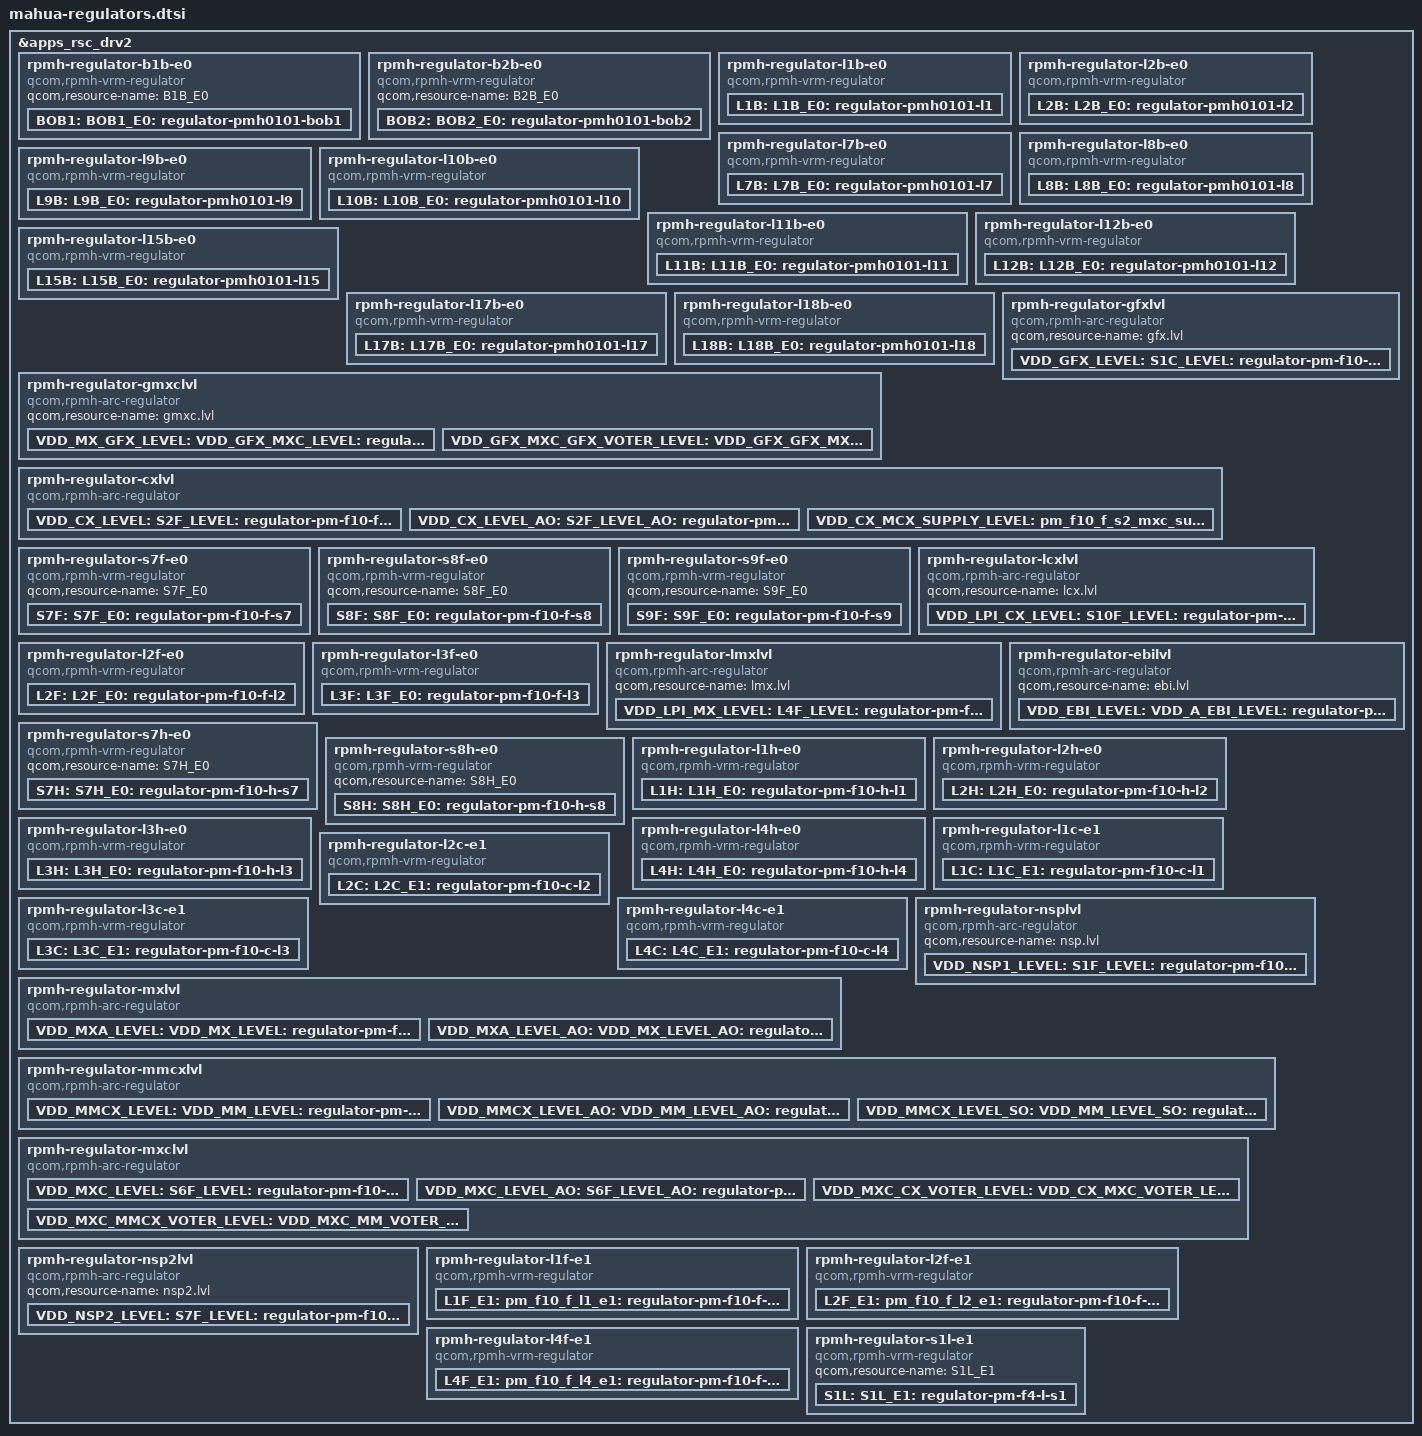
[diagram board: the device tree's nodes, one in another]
// SPDX-License-Identifier: BSD-3-Clause
/*
 * Copyright (c) Qualcomm Technologies, Inc. and/or its subsidiaries.
 */

#include <dt-bindings/regulator/qcom,rpmh-regulator-levels.h>

&apps_rsc_drv2 {
	rpmh-regulator-b1b-e0 {
		compatible = "qcom,rpmh-vrm-regulator";
		qcom,resource-name = "B1B_E0";

		BOB1: BOB1_E0: pmh0101_bob1: regulator-pmh0101-bob1 {
			regulator-name = "pmh0101_bob1";
			qcom,set = <RPMH_REGULATOR_SET_ALL>;
			regulator-min-microvolt = <3300000>;
			regulator-max-microvolt = <4224000>;
			qcom,init-voltage = <3424000>;
		};
	};

	rpmh-regulator-b2b-e0 {
		compatible = "qcom,rpmh-vrm-regulator";
		qcom,resource-name = "B2B_E0";

		BOB2: BOB2_E0: pmh0101_bob2: regulator-pmh0101-bob2 {
			regulator-name = "pmh0101_bob2";
			qcom,set = <RPMH_REGULATOR_SET_ALL>;
			regulator-min-microvolt = <2720000>;
			regulator-max-microvolt = <3008000>;
			qcom,init-voltage = <2720000>;
		};
	};

	rpmh-regulator-l1b-e0 {
		compatible = "qcom,rpmh-vrm-regulator";
		qcom,resource-name = "L1B_E0";
		qcom,regulator-type = "pmic7-ldo";
		qcom,supported-modes = <RPMH_REGULATOR_MODE_LPM
					RPMH_REGULATOR_MODE_HPM>;
		qcom,mode-threshold-currents = <0 30000>;

		L1B: L1B_E0: pmh0101_l1: regulator-pmh0101-l1 {
			regulator-name = "pmh0101_l1";
			qcom,set = <RPMH_REGULATOR_SET_ALL>;
			regulator-min-microvolt = <1800000>;
			regulator-max-microvolt = <1800000>;
			qcom,init-voltage = <1800000>;
			qcom,init-mode = <RPMH_REGULATOR_MODE_HPM>;
		};
	};

	rpmh-regulator-l2b-e0 {
		compatible = "qcom,rpmh-vrm-regulator";
		qcom,resource-name = "L2B_E0";
		qcom,regulator-type = "pmic7-ldo";
		qcom,supported-modes = <RPMH_REGULATOR_MODE_LPM
					RPMH_REGULATOR_MODE_HPM>;
		qcom,mode-threshold-currents = <0 20000>;

		L2B: L2B_E0: pmh0101_l2: regulator-pmh0101-l2 {
			regulator-name = "pmh0101_l2";
			qcom,set = <RPMH_REGULATOR_SET_ALL>;
			regulator-min-microvolt = <1800000>;
			regulator-max-microvolt = <3300000>;
			qcom,init-voltage = <3300000>;
			qcom,init-mode = <RPMH_REGULATOR_MODE_HPM>;
		};
	};

	rpmh-regulator-l7b-e0 {
		compatible = "qcom,rpmh-vrm-regulator";
		qcom,resource-name = "L7B_E0";
		qcom,regulator-type = "pmic7-ldo";
		qcom,supported-modes = <RPMH_REGULATOR_MODE_LPM
					RPMH_REGULATOR_MODE_HPM>;
		qcom,mode-threshold-currents = <0 20000>;

		L7B: L7B_E0: pmh0101_l7: regulator-pmh0101-l7 {
			regulator-name = "pmh0101_l7";
			qcom,set = <RPMH_REGULATOR_SET_ALL>;
			regulator-min-microvolt = <3000000>;
			regulator-max-microvolt = <3300000>;
			qcom,init-voltage = <3000000>;
			qcom,init-mode = <RPMH_REGULATOR_MODE_HPM>;
		};
	};

	rpmh-regulator-l8b-e0 {
		compatible = "qcom,rpmh-vrm-regulator";
		qcom,resource-name = "L8B_E0";
		qcom,regulator-type = "pmic7-ldo";
		qcom,supported-modes = <RPMH_REGULATOR_MODE_LPM
					RPMH_REGULATOR_MODE_HPM>;
		qcom,mode-threshold-currents = <0 10000>;

		L8B: L8B_E0: pmh0101_l8: regulator-pmh0101-l8 {
			regulator-name = "pmh0101_l8";
			qcom,set = <RPMH_REGULATOR_SET_ALL>;
			regulator-min-microvolt = <3304000>;
			regulator-max-microvolt = <3400000>;
			qcom,init-voltage = <3304000>;
			qcom,init-mode = <RPMH_REGULATOR_MODE_HPM>;
		};
	};

	rpmh-regulator-l9b-e0 {
		compatible = "qcom,rpmh-vrm-regulator";
		qcom,resource-name = "L9B_E0";
		qcom,regulator-type = "pmic7-ldo";
		qcom,supported-modes = <RPMH_REGULATOR_MODE_LPM
					RPMH_REGULATOR_MODE_HPM>;
		qcom,mode-threshold-currents = <0 80000>;

		L9B: L9B_E0: pmh0101_l9: regulator-pmh0101-l9 {
			regulator-name = "pmh0101_l9";
			qcom,set = <RPMH_REGULATOR_SET_ALL>;
			regulator-min-microvolt = <2960000>;
			regulator-max-microvolt = <2960000>;
			qcom,init-voltage = <2960000>;
			qcom,init-mode = <RPMH_REGULATOR_MODE_HPM>;
		};
	};

	rpmh-regulator-l10b-e0 {
		compatible = "qcom,rpmh-vrm-regulator";
		qcom,resource-name = "L10B_E0";
		qcom,regulator-type = "pmic7-ldo";
		qcom,supported-modes = <RPMH_REGULATOR_MODE_LPM
					RPMH_REGULATOR_MODE_HPM>;
		qcom,mode-threshold-currents = <0 30000>;

		L10B: L10B_E0: pmh0101_l10: regulator-pmh0101-l10 {
			regulator-name = "pmh0101_l10";
			qcom,set = <RPMH_REGULATOR_SET_ALL>;
			regulator-min-microvolt = <1800000>;
			regulator-max-microvolt = <1800000>;
			qcom,init-voltage = <1800000>;
			qcom,init-mode = <RPMH_REGULATOR_MODE_HPM>;
		};
	};

	rpmh-regulator-l11b-e0 {
		compatible = "qcom,rpmh-vrm-regulator";
		qcom,resource-name = "L11B_E0";
		qcom,regulator-type = "pmic7-ldo";
		qcom,supported-modes = <RPMH_REGULATOR_MODE_LPM
					RPMH_REGULATOR_MODE_HPM>;
		qcom,mode-threshold-currents = <0 30000>;

		L11B: L11B_E0: pmh0101_l11: regulator-pmh0101-l11 {
			regulator-name = "pmh0101_l11";
			qcom,set = <RPMH_REGULATOR_SET_ALL>;
			regulator-min-microvolt = <1200000>;
			regulator-max-microvolt = <1200000>;
			qcom,init-voltage = <1200000>;
			qcom,init-mode = <RPMH_REGULATOR_MODE_HPM>;
		};
	};

	rpmh-regulator-l12b-e0 {
		compatible = "qcom,rpmh-vrm-regulator";
		qcom,resource-name = "L12B_E0";
		qcom,regulator-type = "pmic7-ldo";
		qcom,supported-modes = <RPMH_REGULATOR_MODE_LPM
					RPMH_REGULATOR_MODE_HPM>;
		qcom,mode-threshold-currents = <0 30000>;

		L12B: L12B_E0: pmh0101_l12: regulator-pmh0101-l12 {
			regulator-name = "pmh0101_l12";
			qcom,set = <RPMH_REGULATOR_SET_ALL>;
			regulator-min-microvolt = <1200000>;
			regulator-max-microvolt = <1260000>;
			qcom,init-voltage = <1200000>;
			qcom,init-mode = <RPMH_REGULATOR_MODE_HPM>;
		};
	};

	rpmh-regulator-l15b-e0 {
		compatible = "qcom,rpmh-vrm-regulator";
		qcom,resource-name = "L15B_E0";
		qcom,regulator-type = "pmic7-ldo";
		qcom,supported-modes = <RPMH_REGULATOR_MODE_LPM
					RPMH_REGULATOR_MODE_HPM>;
		qcom,mode-threshold-currents = <0 30000>;

		L15B: L15B_E0: pmh0101_l15: regulator-pmh0101-l15 {
			regulator-name = "pmh0101_l15";
			qcom,set = <RPMH_REGULATOR_SET_ALL>;
			regulator-min-microvolt = <1800000>;
			regulator-max-microvolt = <1800000>;
			qcom,init-voltage = <1800000>;
			qcom,init-mode = <RPMH_REGULATOR_MODE_HPM>;
		};
	};

	rpmh-regulator-l17b-e0 {
		compatible = "qcom,rpmh-vrm-regulator";
		qcom,resource-name = "L17B_E0";
		qcom,regulator-type = "pmic7-ldo";
		qcom,supported-modes = <RPMH_REGULATOR_MODE_LPM
					RPMH_REGULATOR_MODE_HPM>;
		qcom,mode-threshold-currents = <0 80000>;

		L17B: L17B_E0: pmh0101_l17: regulator-pmh0101-l17 {
			regulator-name = "pmh0101_l17";
			qcom,set = <RPMH_REGULATOR_SET_ALL>;
			regulator-min-microvolt = <2500000>;
			regulator-max-microvolt = <2600000>;
			qcom,init-voltage = <2504000>;
			qcom,init-mode = <RPMH_REGULATOR_MODE_HPM>;
		};
	};

	rpmh-regulator-l18b-e0 {
		compatible = "qcom,rpmh-vrm-regulator";
		qcom,resource-name = "L18B_E0";
		qcom,regulator-type = "pmic7-ldo";
		qcom,supported-modes = <RPMH_REGULATOR_MODE_LPM
					RPMH_REGULATOR_MODE_HPM>;
		qcom,mode-threshold-currents = <0 30000>;

		L18B: L18B_E0: pmh0101_l18: regulator-pmh0101-l18 {
			regulator-name = "pmh0101_l18";
			qcom,set = <RPMH_REGULATOR_SET_ALL>;
			regulator-min-microvolt = <1200000>;
			regulator-max-microvolt = <1200000>;
			qcom,init-voltage = <1200000>;
			qcom,init-mode = <RPMH_REGULATOR_MODE_HPM>;
		};
	};

	rpmh-regulator-gfxlvl {
		compatible = "qcom,rpmh-arc-regulator";
		qcom,resource-name = "gfx.lvl";

		VDD_GFX_LEVEL: S1C_LEVEL: S1C_E0_LEVEL:
		pm_f10_c_s1_level: regulator-pm-f10-c-s1-level {
			regulator-name = "pm_f10_c_s1_level";
			qcom,set = <RPMH_REGULATOR_SET_ALL>;
			regulator-min-microvolt =
				<RPMH_REGULATOR_LEVEL_RETENTION>;
			regulator-max-microvolt =
				<RPMH_REGULATOR_LEVEL_MAX>;
			qcom,init-voltage-level =
				<RPMH_REGULATOR_LEVEL_RETENTION>;
		};
	};

	rpmh-regulator-gmxclvl {
		compatible = "qcom,rpmh-arc-regulator";
		qcom,resource-name = "gmxc.lvl";

		VDD_MX_GFX_LEVEL: VDD_GFX_MXC_LEVEL: S8C_LEVEL: S8C_E0_LEVEL:
		pm_f10_c_s8_level: regulator-pm-f10-c-s8-level {
			regulator-name = "pm_f10_c_s8_level";
			qcom,set = <RPMH_REGULATOR_SET_ALL>;
			regulator-min-microvolt =
				<RPMH_REGULATOR_LEVEL_RETENTION>;
			regulator-max-microvolt =
				<RPMH_REGULATOR_LEVEL_MAX>;
			qcom,init-voltage-level =
				<RPMH_REGULATOR_LEVEL_RETENTION>;
		};

		VDD_GFX_MXC_GFX_VOTER_LEVEL: VDD_GFX_GFX_MXC_VOTER_LEVEL:
		regulator-pm-f10-c-s8-gfx-voter-level {
			regulator-name = "pm_f10_c_s8_gfx_voter_level";
			qcom,set = <RPMH_REGULATOR_SET_ALL>;
			pm_f10_c_s8_gfx_voter_level-parent-supply =
				<&VDD_GFX_LEVEL>;
			regulator-min-microvolt =
				<RPMH_REGULATOR_LEVEL_MIN_SVS>;
			regulator-max-microvolt =
				<RPMH_REGULATOR_LEVEL_MAX>;
			qcom,init-voltage-level =
				<RPMH_REGULATOR_LEVEL_MIN_SVS>;
		};
	};

	rpmh-regulator-cxlvl {
		compatible = "qcom,rpmh-arc-regulator";
		qcom,resource-name = "cx.lvl";
		proxy-supply = <&VDD_CX_LEVEL>;

		VDD_CX_LEVEL: S2F_LEVEL: S2F_E0_LEVEL:
			pm_f10_f_s2_level: regulator-pm-f10-f-s2-level {
			regulator-name = "pm_f10_f_s2_level";
			qcom,set = <RPMH_REGULATOR_SET_ALL>;
			regulator-min-microvolt =
				<RPMH_REGULATOR_LEVEL_RETENTION>;
			regulator-max-microvolt =
				<RPMH_REGULATOR_LEVEL_MAX>;
			qcom,init-voltage-level =
				<RPMH_REGULATOR_LEVEL_TURBO>;
			qcom,proxy-consumer-enable;
			qcom,proxy-consumer-voltage =
				<RPMH_REGULATOR_LEVEL_TURBO
				RPMH_REGULATOR_LEVEL_MAX>;
		};

		VDD_CX_LEVEL_AO: S2F_LEVEL_AO: S2F_E0_LEVEL_AO:
			pm_f10_f_s2_level_ao: regulator-pm-f10-f-s2-level-ao {
			regulator-name = "pm_f10_f_s2_level_ao";
			qcom,set = <RPMH_REGULATOR_SET_ACTIVE>;
			regulator-min-microvolt =
				<RPMH_REGULATOR_LEVEL_RETENTION>;
			regulator-max-microvolt =
				<RPMH_REGULATOR_LEVEL_MAX>;
			qcom,init-voltage-level =
				<RPMH_REGULATOR_LEVEL_RETENTION>;
		};

		VDD_CX_MCX_SUPPLY_LEVEL:
		pm_f10_f_s2_mxc_sup_level: regulator-pm-f10-s2-mxc-sup-level {
			regulator-name = "pm_f10_f_s2_mxc_sup_level";
			qcom,set = <RPMH_REGULATOR_SET_ALL>;
			regulator-min-microvolt =
				<RPMH_REGULATOR_LEVEL_MIN_SVS>;
			regulator-max-microvolt =
				<RPMH_REGULATOR_LEVEL_MAX>;
			qcom,init-voltage-level =
				<RPMH_REGULATOR_LEVEL_MIN_SVS>;
		};
	};

	rpmh-regulator-s7f-e0 {
		compatible = "qcom,rpmh-vrm-regulator";
		qcom,resource-name = "S7F_E0";

		S7F: S7F_E0: pm_f10_f_s7: regulator-pm-f10-f-s7 {
			regulator-name = "pm_f10_f_s7";
			qcom,set = <RPMH_REGULATOR_SET_ALL>;
			regulator-min-microvolt = <1320000>;
			regulator-max-microvolt = <1352000>;
			qcom,init-voltage = <1320000>;
		};
	};

	rpmh-regulator-s8f-e0 {
		compatible = "qcom,rpmh-vrm-regulator";
		qcom,resource-name = "S8F_E0";

		S8F: S8F_E0: pm_f10_f_s8: regulator-pm-f10-f-s8 {
			regulator-name = "pm_f10_f_s8";
			qcom,set = <RPMH_REGULATOR_SET_ALL>;
			regulator-min-microvolt = <952000>;
			regulator-max-microvolt = <1100000>;
			qcom,init-voltage = <952000>;
		};
	};

	rpmh-regulator-s9f-e0 {
		compatible = "qcom,rpmh-vrm-regulator";
		qcom,resource-name = "S9F_E0";

		S9F: S9F_E0: pm_f10_f_s9: regulator-pm-f10-f-s9 {
			regulator-name = "pm_f10_f_s9";
			qcom,set = <RPMH_REGULATOR_SET_ALL>;
			regulator-min-microvolt = <1900000>;
			regulator-max-microvolt = <2000000>;
			qcom,init-voltage = <1900000>;
		};
	};

	rpmh-regulator-lcxlvl {
		compatible = "qcom,rpmh-arc-regulator";
		qcom,resource-name = "lcx.lvl";

		VDD_LPI_CX_LEVEL: S10F_LEVEL: S10F_E0_LEVEL:
		pm_f10_f_s10_level: regulator-pm-f10-f-s10-level {
			regulator-name = "pm_f10_f_s10_level";
			qcom,set = <RPMH_REGULATOR_SET_ALL>;
			regulator-min-microvolt =
				<RPMH_REGULATOR_LEVEL_RETENTION>;
			regulator-max-microvolt =
				<RPMH_REGULATOR_LEVEL_MAX>;
			qcom,init-voltage-level =
				<RPMH_REGULATOR_LEVEL_RETENTION>;
		};
	};

	rpmh-regulator-l2f-e0 {
		compatible = "qcom,rpmh-vrm-regulator";
		qcom,resource-name = "L2F_E0";
		qcom,regulator-type = "pmic7-ldo";
		qcom,supported-modes = <RPMH_REGULATOR_MODE_LPM
					RPMH_REGULATOR_MODE_HPM>;
		qcom,mode-threshold-currents = <0 30000>;

		L2F: L2F_E0: pm_f10_f_l2: regulator-pm-f10-f-l2 {
			regulator-name = "pm_f10_f_l2";
			qcom,set = <RPMH_REGULATOR_SET_ALL>;
			regulator-min-microvolt = <936000>;
			regulator-max-microvolt = <952000>;
			qcom,init-voltage = <944000>;
			qcom,init-mode = <RPMH_REGULATOR_MODE_HPM>;
		};
	};

	rpmh-regulator-l3f-e0 {
		compatible = "qcom,rpmh-vrm-regulator";
		qcom,resource-name = "L3F_E0";
		qcom,regulator-type = "pmic7-ldo";
		qcom,supported-modes = <RPMH_REGULATOR_MODE_LPM
					RPMH_REGULATOR_MODE_HPM>;
		qcom,mode-threshold-currents = <0 30000>;

		L3F: L3F_E0: pm_f10_f_l3: regulator-pm-f10-f-l3 {
			regulator-name = "pm_f10_f_l3";
			qcom,set = <RPMH_REGULATOR_SET_ALL>;
			regulator-min-microvolt = <912000>;
			regulator-max-microvolt = <952000>;
			qcom,init-voltage = <912000>;
			qcom,init-mode = <RPMH_REGULATOR_MODE_HPM>;
		};
	};

	rpmh-regulator-lmxlvl {
		compatible = "qcom,rpmh-arc-regulator";
		qcom,resource-name = "lmx.lvl";

		VDD_LPI_MX_LEVEL:
		L4F_LEVEL: L4F_E0_LEVEL:
		pm_f10_f_l4_level: regulator-pm-f10-f-l4-level {
			regulator-name = "pm_f10_f_l4_level";
			qcom,set = <RPMH_REGULATOR_SET_ALL>;
			regulator-min-microvolt =
				<RPMH_REGULATOR_LEVEL_RETENTION>;
			regulator-max-microvolt =
				<RPMH_REGULATOR_LEVEL_MAX>;
			qcom,init-voltage-level =
				<RPMH_REGULATOR_LEVEL_RETENTION>;
		};
	};

	rpmh-regulator-ebilvl {
		compatible = "qcom,rpmh-arc-regulator";
		qcom,resource-name = "ebi.lvl";

		VDD_EBI_LEVEL: VDD_A_EBI_LEVEL: S6H_LEVEL: S6H_E0_LEVEL:
		pm_f10_h_s6_level: regulator-pm-f10-h-s6-level {
			regulator-name = "pm_f10_h_s6_level";
			qcom,set = <RPMH_REGULATOR_SET_ALL>;
			regulator-min-microvolt =
				<RPMH_REGULATOR_LEVEL_RETENTION>;
			regulator-max-microvolt =
				<RPMH_REGULATOR_LEVEL_MAX>;
			qcom,init-voltage-level =
				<RPMH_REGULATOR_LEVEL_RETENTION>;
		};
	};

	rpmh-regulator-s7h-e0 {
		compatible = "qcom,rpmh-vrm-regulator";
		qcom,resource-name = "S7H_E0";

		S7H: S7H_E0: pm_f10_h_s7: regulator-pm-f10-h-s7 {
			regulator-name = "pm_f10_h_s7";
			qcom,set = <RPMH_REGULATOR_SET_ALL>;
			regulator-min-microvolt = <870000>;
			regulator-max-microvolt = <1100000>;
			qcom,init-voltage = <904000>;
		};
	};

	rpmh-regulator-s8h-e0 {
		compatible = "qcom,rpmh-vrm-regulator";
		qcom,resource-name = "S8H_E0";

		S8H: S8H_E0: pm_f10_h_s8: regulator-pm-f10-h-s8 {
			regulator-name = "pm_f10_h_s8";
			qcom,set = <RPMH_REGULATOR_SET_ALL>;
			regulator-min-microvolt = <300000>;
			regulator-max-microvolt = <570000>;
			qcom,init-voltage = <500000>;
		};
	};

	rpmh-regulator-l1h-e0 {
		compatible = "qcom,rpmh-vrm-regulator";
		qcom,resource-name = "L1H_E0";
		qcom,regulator-type = "pmic7-ldo";
		qcom,supported-modes = <RPMH_REGULATOR_MODE_LPM
					RPMH_REGULATOR_MODE_HPM>;
		qcom,mode-threshold-currents = <0 30000>;

		L1H: L1H_E0: pm_f10_h_l1: regulator-pm-f10-h-l1 {
			regulator-name = "pm_f10_h_l1";
			qcom,set = <RPMH_REGULATOR_SET_ALL>;
			regulator-min-microvolt = <912000>;
			regulator-max-microvolt = <952000>;
			qcom,init-voltage = <936000>;
			qcom,init-mode = <RPMH_REGULATOR_MODE_HPM>;
		};
	};

	rpmh-regulator-l2h-e0 {
		compatible = "qcom,rpmh-vrm-regulator";
		qcom,resource-name = "L2H_E0";
		qcom,regulator-type = "pmic7-ldo";
		qcom,supported-modes = <RPMH_REGULATOR_MODE_LPM
					RPMH_REGULATOR_MODE_HPM>;
		qcom,mode-threshold-currents = <0 30000>;

		L2H: L2H_E0: pm_f10_h_l2: regulator-pm-f10-h-l2 {
			regulator-name = "pm_f10_h_l2";
			qcom,set = <RPMH_REGULATOR_SET_ALL>;
			regulator-min-microvolt = <880000>;
			regulator-max-microvolt = <952000>;
			qcom,init-voltage = <880000>;
			qcom,init-mode = <RPMH_REGULATOR_MODE_HPM>;
		};
	};

	rpmh-regulator-l3h-e0 {
		compatible = "qcom,rpmh-vrm-regulator";
		qcom,resource-name = "L3H_E0";
		qcom,regulator-type = "pmic7-ldo";
		qcom,supported-modes = <RPMH_REGULATOR_MODE_LPM
					RPMH_REGULATOR_MODE_HPM>;
		qcom,mode-threshold-currents = <0 30000>;

		L3H: L3H_E0: pm_f10_h_l3: regulator-pm-f10-h-l3 {
			regulator-name = "pm_f10_h_l3";
			qcom,set = <RPMH_REGULATOR_SET_ALL>;
			regulator-min-microvolt = <1800000>;
			regulator-max-microvolt = <1800000>;
			qcom,init-voltage = <1800000>;
			qcom,init-mode = <RPMH_REGULATOR_MODE_HPM>;
		};
	};

	rpmh-regulator-l4h-e0 {
		compatible = "qcom,rpmh-vrm-regulator";
		qcom,resource-name = "L4H_E0";
		qcom,regulator-type = "pmic7-ldo";
		qcom,supported-modes = <RPMH_REGULATOR_MODE_LPM
					RPMH_REGULATOR_MODE_HPM>;
		qcom,mode-threshold-currents = <0 30000>;

		L4H: L4H_E0: pm_f10_h_l4: regulator-pm-f10-h-l4 {
			regulator-name = "pm_f10_h_l4";
			qcom,set = <RPMH_REGULATOR_SET_ALL>;
			regulator-min-microvolt = <1200000>;
			regulator-max-microvolt = <1200000>;
			qcom,init-voltage = <1200000>;
			qcom,init-mode = <RPMH_REGULATOR_MODE_HPM>;
		};
	};

	rpmh-regulator-l1c-e1 {
		compatible = "qcom,rpmh-vrm-regulator";
		qcom,resource-name = "L1C_E1";
		qcom,regulator-type = "pmic7-ldo";
		qcom,supported-modes = <RPMH_REGULATOR_MODE_LPM
					RPMH_REGULATOR_MODE_HPM>;
		qcom,mode-threshold-currents = <0 30000>;

		L1C: L1C_E1: pm_f10_c_l1: regulator-pm-f10-c-l1 {
			regulator-name = "pm_f10_c_l1";
			qcom,set = <RPMH_REGULATOR_SET_ALL>;
			regulator-min-microvolt = <912000>;
			regulator-max-microvolt = <952000>;
			qcom,init-voltage = <912000>;
			qcom,init-mode = <RPMH_REGULATOR_MODE_HPM>;
		};
	};

	rpmh-regulator-l2c-e1 {
		compatible = "qcom,rpmh-vrm-regulator";
		qcom,resource-name = "L2C_E1";
		qcom,regulator-type = "pmic7-ldo";
		qcom,supported-modes = <RPMH_REGULATOR_MODE_LPM
					RPMH_REGULATOR_MODE_HPM>;
		qcom,mode-threshold-currents = <0 30000>;

		L2C: L2C_E1: pm_f10_c_l2: regulator-pm-f10-c-l2 {
			regulator-name = "pm_f10_c_l2";
			qcom,set = <RPMH_REGULATOR_SET_ALL>;
			regulator-min-microvolt = <1200000>;
			regulator-max-microvolt = <1252000>;
			qcom,init-voltage = <1216000>;
			qcom,init-mode = <RPMH_REGULATOR_MODE_HPM>;
		};
	};

	rpmh-regulator-l3c-e1 {
		compatible = "qcom,rpmh-vrm-regulator";
		qcom,resource-name = "L3C_E1";
		qcom,regulator-type = "pmic7-ldo";
		qcom,supported-modes = <RPMH_REGULATOR_MODE_LPM
					RPMH_REGULATOR_MODE_HPM>;
		qcom,mode-threshold-currents = <0 30000>;

		L3C: L3C_E1: pm_f10_c_l3: regulator-pm-f10-c-l3 {
			regulator-name = "pm_f10_c_l3";
			qcom,set = <RPMH_REGULATOR_SET_ALL>;
			regulator-min-microvolt = <936000>;
			regulator-max-microvolt = <952000>;
			qcom,init-voltage = <936000>;
			qcom,init-mode = <RPMH_REGULATOR_MODE_HPM>;
		};
	};

	rpmh-regulator-l4c-e1 {
		compatible = "qcom,rpmh-vrm-regulator";
		qcom,resource-name = "L4C_E1";
		qcom,regulator-type = "pmic7-ldo";
		qcom,supported-modes = <RPMH_REGULATOR_MODE_LPM
					RPMH_REGULATOR_MODE_HPM>;
		qcom,mode-threshold-currents = <0 30000>;

		L4C: L4C_E1: pm_f10_c_l4: regulator-pm-f10-c-l4 {
			regulator-name = "pm_f10_c_l4";
			qcom,set = <RPMH_REGULATOR_SET_ALL>;
			regulator-min-microvolt = <912000>;
			regulator-max-microvolt = <952000>;
			qcom,init-voltage = <912000>;
			qcom,init-mode = <RPMH_REGULATOR_MODE_HPM>;
		};
	};

	rpmh-regulator-nsplvl {
		compatible = "qcom,rpmh-arc-regulator";
		qcom,resource-name = "nsp.lvl";

		VDD_NSP1_LEVEL: S1F_LEVEL: S1F_E1_LEVEL:
		pm_f10_f_s1_level: regulator-pm-f10-f-s1-level {
			regulator-name = "pm_f10_f_s1_level";
			qcom,set = <RPMH_REGULATOR_SET_ALL>;
			regulator-min-microvolt =
				<RPMH_REGULATOR_LEVEL_RETENTION>;
			regulator-max-microvolt =
				<RPMH_REGULATOR_LEVEL_MAX>;
			qcom,init-voltage-level =
				<RPMH_REGULATOR_LEVEL_RETENTION>;
		};
	};

	rpmh-regulator-mxlvl {
		compatible = "qcom,rpmh-arc-regulator";
		qcom,resource-name = "mx.lvl";
		proxy-supply = <&VDD_MXA_LEVEL>;

		VDD_MXA_LEVEL: VDD_MX_LEVEL: S5F_LEVEL: S5F_E1_LEVEL:
		pm_f10_f_s5_level: regulator-pm-f10-f-s5-level {
			regulator-name = "pm_f10_f_s5_level";
			qcom,set = <RPMH_REGULATOR_SET_ALL>;
			regulator-min-microvolt =
				<RPMH_REGULATOR_LEVEL_RETENTION>;
			regulator-max-microvolt =
				<RPMH_REGULATOR_LEVEL_MAX>;
			qcom,init-voltage-level =
				<RPMH_REGULATOR_LEVEL_TURBO>;
			qcom,proxy-consumer-enable;
			qcom,proxy-consumer-voltage =
				<RPMH_REGULATOR_LEVEL_TURBO
				RPMH_REGULATOR_LEVEL_MAX>;
		};

		VDD_MXA_LEVEL_AO: VDD_MX_LEVEL_AO: S5F_LEVEL_AO: S5F_E1_LEVEL_AO:
		pm_f10_f_s5_level_ao: regulator-pm-f10-f-s5-level-ao {
			regulator-name = "pm_f10_f_s5_level_ao";
			qcom,set = <RPMH_REGULATOR_SET_ACTIVE>;
			regulator-min-microvolt =
				<RPMH_REGULATOR_LEVEL_RETENTION>;
			regulator-max-microvolt =
				<RPMH_REGULATOR_LEVEL_MAX>;
			qcom,init-voltage-level =
				<RPMH_REGULATOR_LEVEL_RETENTION>;
		};
	};

	rpmh-regulator-mmcxlvl {
		compatible = "qcom,rpmh-arc-regulator";
		qcom,resource-name = "mmcx.lvl";
		proxy-supply = <&VDD_MMCX_LEVEL>;

		VDD_MMCX_LEVEL: VDD_MM_LEVEL: S3F_LEVEL: S3F_E1_LEVEL:
		pm_f10_f_s3_level: regulator-pm-f10-f-s3-level {
			regulator-name = "pm_f10_f_s3_level";
			qcom,set = <RPMH_REGULATOR_SET_ALL>;
			regulator-min-microvolt =
				<RPMH_REGULATOR_LEVEL_LOW_SVS_D1>;
			regulator-max-microvolt =
				<RPMH_REGULATOR_LEVEL_MAX>;
			qcom,init-voltage-level =
				<RPMH_REGULATOR_LEVEL_TURBO>;
			qcom,proxy-consumer-enable;
			qcom,proxy-consumer-voltage =
				<RPMH_REGULATOR_LEVEL_TURBO
				RPMH_REGULATOR_LEVEL_MAX>;
		};

		VDD_MMCX_LEVEL_AO: VDD_MM_LEVEL_AO: S3F_LEVEL_AO: S3F_E1_LEVEL_AO:
		pm_f10_f_s3_level_ao: regulator-pm-f10-f-s3-level-ao {
			regulator-name = "pm_f10_f_s3_level_ao";
			qcom,set = <RPMH_REGULATOR_SET_ACTIVE>;
			regulator-min-microvolt =
				<RPMH_REGULATOR_LEVEL_LOW_SVS_D1>;
			regulator-max-microvolt =
				<RPMH_REGULATOR_LEVEL_MAX>;
			qcom,init-voltage-level =
				<RPMH_REGULATOR_LEVEL_LOW_SVS_D1>;
		};

		VDD_MMCX_LEVEL_SO: VDD_MM_LEVEL_SO: S3F_LEVEL_SO: S3F_E1_LEVEL_SO:
		pm_f10_f_s3_level_so: regulator-pm-f10-f-s3-level-so {
			regulator-name = "pm_f10_f_s3_level_so";
			qcom,set = <RPMH_REGULATOR_SET_SLEEP>;
			regulator-min-microvolt =
				<RPMH_REGULATOR_LEVEL_LOW_SVS_D1>;
			regulator-max-microvolt =
				<RPMH_REGULATOR_LEVEL_MAX>;
			qcom,init-voltage-level =
				<RPMH_REGULATOR_LEVEL_LOW_SVS_D1>;
		};
	};

	rpmh-regulator-mxclvl {
		compatible = "qcom,rpmh-arc-regulator";
		qcom,resource-name = "mxc.lvl";
		proxy-supply = <&VDD_MXC_LEVEL>;

		VDD_MXC_LEVEL: S6F_LEVEL: S6F_E1_LEVEL:
		pm_f10_f_s6_level: regulator-pm-f10-f-s6-level {
			regulator-name = "pm_f10_f_s6_level";
			qcom,set = <RPMH_REGULATOR_SET_ALL>;
			regulator-min-microvolt =
				<RPMH_REGULATOR_LEVEL_RETENTION>;
			regulator-max-microvolt =
				<RPMH_REGULATOR_LEVEL_MAX>;
			qcom,init-voltage-level =
				<RPMH_REGULATOR_LEVEL_TURBO>;
			qcom,proxy-consumer-enable;
			qcom,proxy-consumer-voltage =
				<RPMH_REGULATOR_LEVEL_TURBO
				RPMH_REGULATOR_LEVEL_MAX>;
		};

		VDD_MXC_LEVEL_AO: S6F_LEVEL_AO: S6F_E1_LEVEL_AO:
		pm_f10_f_s6_level_ao: regulator-pm-f10-f-s6-level-ao {
			regulator-name = "pm_f10_f_s6_level_ao";
			qcom,set = <RPMH_REGULATOR_SET_ACTIVE>;
			regulator-min-microvolt =
				<RPMH_REGULATOR_LEVEL_RETENTION>;
			regulator-max-microvolt =
				<RPMH_REGULATOR_LEVEL_MAX>;
			qcom,init-voltage-level =
				<RPMH_REGULATOR_LEVEL_RETENTION>;
		};

		VDD_MXC_CX_VOTER_LEVEL: VDD_CX_MXC_VOTER_LEVEL:
		pm_f10_f_s6_cx_voter_level: regulator-pm-f10-f-s6-cx-voter-level {
			regulator-name = "pm_f10_f_s6_cx_voter_level";
			qcom,set = <RPMH_REGULATOR_SET_ALL>;
			pm_f10_f_s6_cx_voter_level-parent-supply =
				<&VDD_CX_MCX_SUPPLY_LEVEL>;
			regulator-min-microvolt =
				<RPMH_REGULATOR_LEVEL_MIN_SVS>;
			regulator-max-microvolt =
				<RPMH_REGULATOR_LEVEL_MAX>;
			qcom,init-voltage-level =
				<RPMH_REGULATOR_LEVEL_MIN_SVS>;
		};

		VDD_MXC_MMCX_VOTER_LEVEL: VDD_MXC_MM_VOTER_LEVEL: VDD_MM_MXC_VOTER_LEVEL:
		pm_f10_f_s6_mmcx_voter_level: regulator-pm-f10-f-s6-mmcx-voter-level {
			regulator-name = "pm_f10_f_s6_mmcx_voter_level";
			qcom,set = <RPMH_REGULATOR_SET_ALL>;
			pm_f10_f_s6_mmcx_voter_level-parent-supply =
				<&VDD_MMCX_LEVEL>;
			regulator-min-microvolt =
				<RPMH_REGULATOR_LEVEL_MIN_SVS>;
			regulator-max-microvolt =
				<RPMH_REGULATOR_LEVEL_MAX>;
			qcom,init-voltage-level =
				<RPMH_REGULATOR_LEVEL_MIN_SVS>;
		};
	};

	rpmh-regulator-nsp2lvl {
		compatible = "qcom,rpmh-arc-regulator";
		qcom,resource-name = "nsp2.lvl";

		VDD_NSP2_LEVEL: S7F_LEVEL: S7F_E1_LEVEL:
		pm_f10_f_s7_level: regulator-pm-f10-f-s7-level {
			regulator-name = "pm_f10_f_s7_level";
			qcom,set = <RPMH_REGULATOR_SET_ALL>;
			regulator-min-microvolt =
				<RPMH_REGULATOR_LEVEL_RETENTION>;
			regulator-max-microvolt =
				<RPMH_REGULATOR_LEVEL_MAX>;
			qcom,init-voltage-level =
				<RPMH_REGULATOR_LEVEL_RETENTION>;
		};
	};

	rpmh-regulator-l1f-e1 {
		compatible = "qcom,rpmh-vrm-regulator";
		qcom,resource-name = "L1F_E1";
		qcom,regulator-type = "pmic7-ldo";
		qcom,supported-modes = <RPMH_REGULATOR_MODE_LPM
					RPMH_REGULATOR_MODE_HPM>;
		qcom,mode-threshold-currents = <0 30000>;

		L1F_E1: pm_f10_f_l1_e1: regulator-pm-f10-f-l1-e1 {
			regulator-name = "pm_f10_f_l1_e1";
			qcom,set = <RPMH_REGULATOR_SET_ALL>;
			regulator-min-microvolt = <880000>;
			regulator-max-microvolt = <952000>;
			qcom,init-voltage = <904000>;
			qcom,init-mode = <RPMH_REGULATOR_MODE_HPM>;
		};
	};

	rpmh-regulator-l2f-e1 {
		compatible = "qcom,rpmh-vrm-regulator";
		qcom,resource-name = "L2F_E1";
		qcom,regulator-type = "pmic7-ldo";
		qcom,supported-modes = <RPMH_REGULATOR_MODE_LPM
					RPMH_REGULATOR_MODE_HPM>;
		qcom,mode-threshold-currents = <0 30000>;

		L2F_E1: pm_f10_f_l2_e1: regulator-pm-f10-f-l2-e1 {
			regulator-name = "pm_f10_f_l2_e1";
			qcom,set = <RPMH_REGULATOR_SET_ALL>;
			regulator-min-microvolt = <880000>;
			regulator-max-microvolt = <952000>;
			qcom,init-voltage = <880000>;
			qcom,init-mode = <RPMH_REGULATOR_MODE_HPM>;
		};
	};

	rpmh-regulator-l4f-e1 {
		compatible = "qcom,rpmh-vrm-regulator";
		qcom,resource-name = "L4F_E1";
		qcom,regulator-type = "pmic7-ldo";
		qcom,supported-modes = <RPMH_REGULATOR_MODE_LPM
					RPMH_REGULATOR_MODE_HPM>;
		qcom,mode-threshold-currents = <0 30000>;

		L4F_E1: pm_f10_f_l4_e1: regulator-pm-f10-f-l4-e1 {
			regulator-name = "pm_f10_f_l4_e1";
			qcom,set = <RPMH_REGULATOR_SET_ALL>;
			regulator-min-microvolt = <1200000>;
			regulator-max-microvolt = <1200000>;
			qcom,init-voltage = <1200000>;
			qcom,init-mode = <RPMH_REGULATOR_MODE_HPM>;
		};
	};

	rpmh-regulator-s1l-e1 {
		compatible = "qcom,rpmh-vrm-regulator";
		qcom,resource-name = "S1L_E1";

		S1L: S1L_E1: pm_f4_l_s1: regulator-pm-f4-l-s1 {
			regulator-name = "pm_f4_l_s1";
			qcom,set = <RPMH_REGULATOR_SET_ALL>;
			regulator-min-microvolt = <500000>;
			regulator-max-microvolt = <1120000>;
			qcom,init-voltage = <1052000>;
		};
	};
};
